# LF1000 register map
Vendor: MagicEyes Digital, Inc.; Series: POLLUX; File version: 1.2
CPU: other r5p0, little endian, MPU, no FPU, I-cache, D-cache, ITCM, DTCM, 0 interrupt priority bits
Registers are 32-bit, read-write, reset 0x0 unless marked. A register's access mark holds for its fields unless they carry their own. Offsets are from the block's base; [hi:lo] are bit positions; lines under a group give offsets from that group; {n}, {i} and the like mark numbered series.

## INTCON — Interrupt controller
Base 0xC0000800
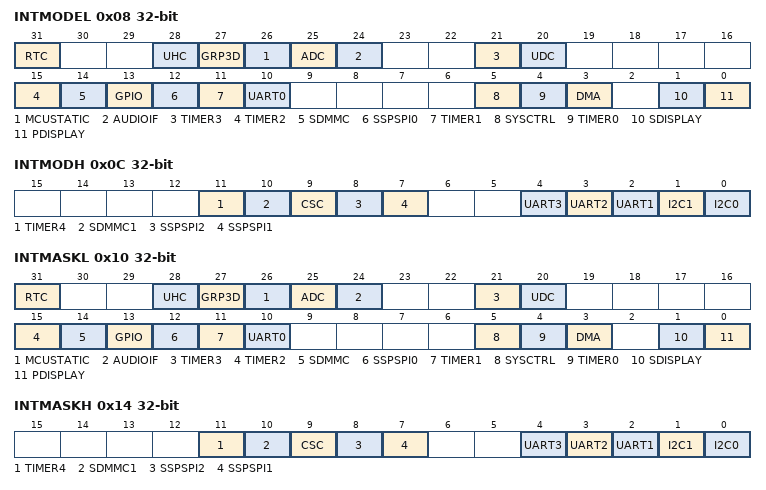
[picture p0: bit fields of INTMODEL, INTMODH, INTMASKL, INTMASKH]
0x08 INTMODEL — Interrupt mode low register
  [all] fields
    0=IRQ; 1=FIQ
  [31] RTC — RTC IRQ/FIQ flag
  [28] UHC — USB host controller IRQ/FIQ flag
  [27] GRP3D — 3D graphics IRQ/FIQ flag
  [26] MCUSTATIC — MCU-S bus IRQ/FIQ flag
  [25] ADC — ADC IRQ/FIQ flag
  [24] AUDIOIF — Audio Interface IRQ/FIQ flag
  [21] TIMER3 — Timer 3 IRQ/FIQ flag
  [20] UDC — USB Device Controller IRQ/FIQ flag
  [15] TIMER2 — Timer 2 IRQ/FIQ flag
  [14] SDMMC — SDMMC IRQ/FIQ flag
  [13] GPIO — GPIO IRQ/FIQ flag
  [12] SSPSPI0 — SSPSPI 0 IRQ/FIQ flag
  [11] TIMER1 — Timer 1 IRQ/FIQ flag
  [10] UART0 — UART 0 IRQ/FIQ flag
  [5] SYSCTRL — System control IRQ/FIQ flag
  [4] TIMER0 — Timer 0 IRQ/FIQ flag
  [3] DMA — DMA controller IRQ/FIQ flag
  [1] SDISPLAY — Secondary display IRQ/FIQ flag
  [0] PDISPLAY — Primary display IRQ/FIQ flag
0x0C INTMODH — Interrupt mode high register
  [all] fields
    0=IRQ; 1=FIQ
  [11] TIMER4 — Timer 4 IRQ/FIQ flag
  [10] SDMMC1 — SDMMC 1 IRQ/FIQ flag
  [9] CSC — CSC IRQ/FIQ flag
  [8] SSPSPI2 — SSPSPI 2 IRQ/FIQ flag
  [7] SSPSPI1 — SSPSPI 1 IRQ/FIQ flag
  [4] UART3 — UART 3 IRQ/FIQ flag
  [3] UART2 — UART 2 IRQ/FIQ flag
  [2] UART1 — UART 1 IRQ/FIQ flag
  [1] I2C1 — I2C 1 IRQ/FIQ flag
  [0] I2C0
0x10 INTMASKL — Interrupt mask low register
  [all] fields
    0=Serviced; 1=Masked
  [31] RTC — RTC mask flag
  [28] UHC — USB host controller mask flag
  [27] GRP3D — 3D graphics mask flag
  [26] MCUSTATIC — MCU-S bus mask flag
  [25] ADC — ADC mask flag
  [24] AUDIOIF — Audio Interface mask flag
  [21] TIMER3 — Timer 3 mask flag
  [20] UDC — USB Device Controller mask flag
  [15] TIMER2 — Timer 2 mask flag
  [14] SDMMC — SDMMC mask flag
  [13] GPIO — GPIO mask flag
  [12] SSPSPI0 — SSPSPI 0 mask flag
  [11] TIMER1 — Timer 1 mask flag
  [10] UART0 — UART 0 mask flag
  [5] SYSCTRL — System control mask flag
  [4] TIMER0 — Timer 0 mask flag
  [3] DMA — DMA controller mask flag
  [1] SDISPLAY — Secondary display mask flag
  [0] PDISPLAY — Primary display mask flag
0x14 INTMASKH — Interrupt mask high register
  [all] fields
    0=Serviced; 1=Masked
  [11] TIMER4 — Timer 4 mask flag
  [10] SDMMC1 — SDMMC 1 mask flag
  [9] CSC — CSC mask flag
  [8] SSPSPI2 — SSPSPI 2 mask flag
  [7] SSPSPI1 — SSPSPI 1 mask flag
  [4] UART3 — UART 3 mask flag
  [3] UART2 — UART 2 mask flag
  [2] UART1 — UART 1 mask flag
  [1] I2C1 — I2C 1 mask flag
  [0] I2C0
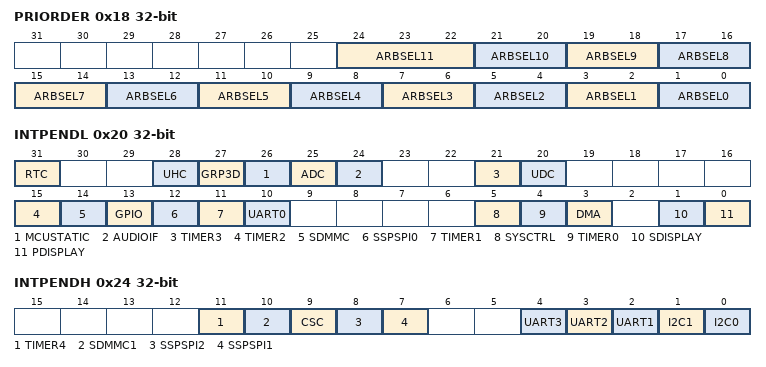
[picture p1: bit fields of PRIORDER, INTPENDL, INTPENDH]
0x18 PRIORDER — Interrupt priority order register
  [24:22] ARBSEL11 — Arbiter group 11 priority order set
    0=REQ 0-1-2-3-4-5-6-7-8-9-10; 1=REQ 0-2-3-4-5-6-7-8-1-9-10; 2=REQ 0-3-4-5-6-7-8-1-2-9-10; 3=REQ 0-4-5-6-7-8-1-2-3-9-10; 4=REQ 0-5-6-7-8-1-2-3-4-9-10; 5=REQ 0-6-7-8-1-2-3-4-5-9-10; 6=REQ 0-7-8-1-2-3-4-5-6-9-10; 7=REQ 0-8-1-2-3-4-5-6-7-9-10
  [2n+1:2n] ARBSEL{n} (n=0..10) — Arbiter group {n} priority order set
    0=REQ 0-1-2-3-4-5; 1=REQ 0-2-3-4-1-5; 2=REQ 0-3-4-1-2-5; 3=REQ 0-4-1-2-3-5
0x20 INTPENDL — Interrupt pending low register
  [all] fields
    0=Not pending; 1=Pending
  [31] RTC — RTC pending flag
  [28] UHC — USB host controller pending flag
  [27] GRP3D — 3D graphics pending flag
  [26] MCUSTATIC — MCU-S bus pending flag
  [25] ADC — ADC pending flag
  [24] AUDIOIF — Audio Interface pending flag
  [21] TIMER3 — Timer 3 pending flag
  [20] UDC — USB Device Controller pending flag
  [15] TIMER2 — Timer 2 pending flag
  [14] SDMMC — SDMMC pending flag
  [13] GPIO — GPIO pending flag
  [12] SSPSPI0 — SSPSPI 0 pending flag
  [11] TIMER1 — Timer 1 pending flag
  [10] UART0 — UART 0 pending flag
  [5] SYSCTRL — System control pending flag
  [4] TIMER0 — Timer 0 pending flag
  [3] DMA — DMA controller pending flag
  [1] SDISPLAY — Secondary display pending flag
  [0] PDISPLAY — Primary display pending flag
0x24 INTPENDH — Interrupt pending high register
  [all] fields
    0=Not pending; 1=Pending
  [11] TIMER4 — Timer 4 pending flag
  [10] SDMMC1 — SDMMC 1 pending flag
  [9] CSC — CSC pending flag
  [8] SSPSPI2 — SSPSPI 2 pending flag
  [7] SSPSPI1 — SSPSPI 1 pending flag
  [4] UART3 — UART 3 pending flag
  [3] UART2 — UART 2 pending flag
  [2] UART1 — UART 1 pending flag
  [1] I2C1 — I2C 1 pending flag
  [0] I2C0
